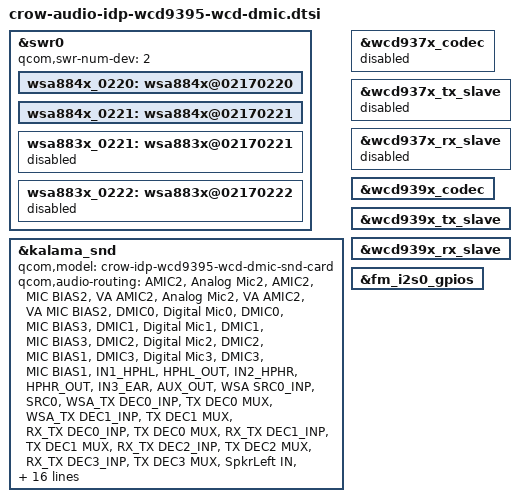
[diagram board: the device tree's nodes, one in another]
#include "crow-audio-overlay.dtsi"

&swr0 {
	qcom,swr-num-dev = <2>;

	wsa884x_0220: wsa884x@02170220 {
		status = "okay";
	};

	wsa884x_0221: wsa884x@02170221 {
		status = "okay";
	};

	wsa883x_0221: wsa883x@02170221 {
		status = "disabled";
	};

	wsa883x_0222: wsa883x@02170222 {
		status = "disabled";
	};
};

&kalama_snd {
	qcom,model = "crow-idp-wcd9395-wcd-dmic-snd-card";
	qcom,audio-routing =
		"AMIC2", "Analog Mic2",
		"AMIC2", "MIC BIAS2",
		"VA AMIC2", "Analog Mic2",
		"VA AMIC2", "VA MIC BIAS2",
		"DMIC0", "Digital Mic0",
		"DMIC0", "MIC BIAS3",
		"DMIC1", "Digital Mic1",
		"DMIC1", "MIC BIAS3",
		"DMIC2", "Digital Mic2",
		"DMIC2", "MIC BIAS1",
		"DMIC3", "Digital Mic3",
		"DMIC3", "MIC BIAS1",
		"IN1_HPHL", "HPHL_OUT",
		"IN2_HPHR", "HPHR_OUT",
		"IN3_EAR", "AUX_OUT",
		"WSA SRC0_INP", "SRC0",
		"WSA_TX DEC0_INP", "TX DEC0 MUX",
		"WSA_TX DEC1_INP", "TX DEC1 MUX",
		"RX_TX DEC0_INP", "TX DEC0 MUX",
		"RX_TX DEC1_INP", "TX DEC1 MUX",
		"RX_TX DEC2_INP", "TX DEC2 MUX",
		"RX_TX DEC3_INP", "TX DEC3 MUX",
		"SpkrLeft IN", "WSA_SPK1 OUT",
		"SpkrRight IN", "WSA_SPK2 OUT",
		"TX SWR_INPUT", "WCD_TX_OUTPUT",
		"VA SWR_INPUT", "VA_SWR_CLK",
		"VA SWR_INPUT", "WCD_TX_OUTPUT",
		"VA_AIF1 CAP", "VA_SWR_CLK",
		"VA_AIF2 CAP", "VA_SWR_CLK",
		"VA_AIF3 CAP", "VA_SWR_CLK",
		"VA DMIC0", "Digital Mic0",
		"VA DMIC2", "Digital Mic2",
		"VA DMIC3", "Digital Mic3",
		"VA DMIC0", "VA MIC BIAS3",
		"VA DMIC2", "VA MIC BIAS1",
		"VA DMIC3", "VA MIC BIAS1";
	asoc-codec = <&stub_codec>, <&lpass_cdc>,
			<&wcd939x_codec>, <&wsa884x_0220>, <&wsa884x_0221>;
	asoc-codec-names = "msm-stub-codec.1", "lpass-cdc",
			"wcd939x_codec", "wsa-codec1", "wsa-codec2";
	wcd939x-i2c-handle = <&wcd_usbss>;
	qcom,ext-disp-audio-rx = <1>;
	qcom,pri-mi2s-gpios = <&fm_i2s0_gpios>;
};

&wcd937x_codec {
	status = "disabled";
};

&wcd937x_tx_slave {
	status = "disabled";
};

&wcd937x_rx_slave {
	status = "disabled";
};

&wcd939x_codec {
	status = "okay";
};

&wcd939x_tx_slave {
	status = "okay";
};

&wcd939x_rx_slave {
	status = "okay";
};

&fm_i2s0_gpios {
	status = "ok";
};
